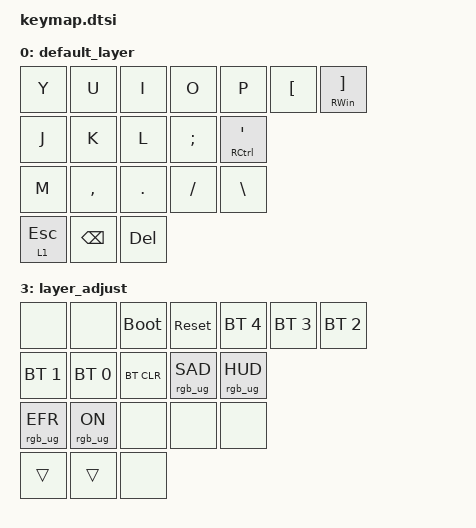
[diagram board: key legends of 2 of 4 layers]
/* SPDX-License-Identifier: MIT */
#include <behaviors.dtsi>
#include <dt-bindings/zmk/bt.h>
#include <dt-bindings/zmk/keys.h>
#include <dt-bindings/zmk/rgb.h>

/ {
    keymap {
        compatible = "zmk,keymap";

        default_layer {
            bindings = <
            &kp Y      &kp U     &kp I      &kp O    &kp P     &kp LBKT       &mt RWIN RBKT
            &kp J      &kp K     &kp L    &kp SEMI  &mt RCTRL SQT
            &kp M      &kp COMMA  &kp DOT  &kp FSLH  &kp BSLH
            &lt 1 ESC  &kp BSPC  &kp DEL
            >;
        };

        layer_lower {
            bindings = <
            &kp F6     &kp F7     &kp F8     &kp F9    &kp F10   &kp F11          &mt RGUI F12
            &kp AMPS  &kp STAR   &kp LPAR  &kp RPAR  &mt RCTRL MINUS
            &kp N7     &kp N8     &kp N9     &kp N0    &trans
            &trans     &lt 3 DEL
            >;
        };

        layer_raise {
            bindings = <
            &kp C_VOL_UP  &kp HOME  &kp PSCRN  &kp PG_UP  &kp SLCK         &kp CAPS
            &kp C_MUTE    &kp LEFT  &kp UP     &kp RIGHT  &kp INS          &mt RCTRL K_APP
            &kp C_VOL_DN  &kp END   &kp DOWN   &kp PG_DN  &kp PAUSE_BREAK
            &lt 3 RET     &lt 3 ESC
            >;
        };

        layer_adjust {
            bindings = <
            &none           &none         &bootloader  &sys_reset
            &bt BT_SEL 4     &bt BT_SEL 3     &bt BT_SEL 2     &bt BT_SEL 1    &bt BT_SEL 0  &bt BT_CLR
            &rgb_ug RGB_SAD  &rgb_ug RGB_HUD  &rgb_ug RGB_EFR  &rgb_ug RGB_ON  &none         &none
            &none            &trans           &trans           &none
            >;
        };
    };
};
